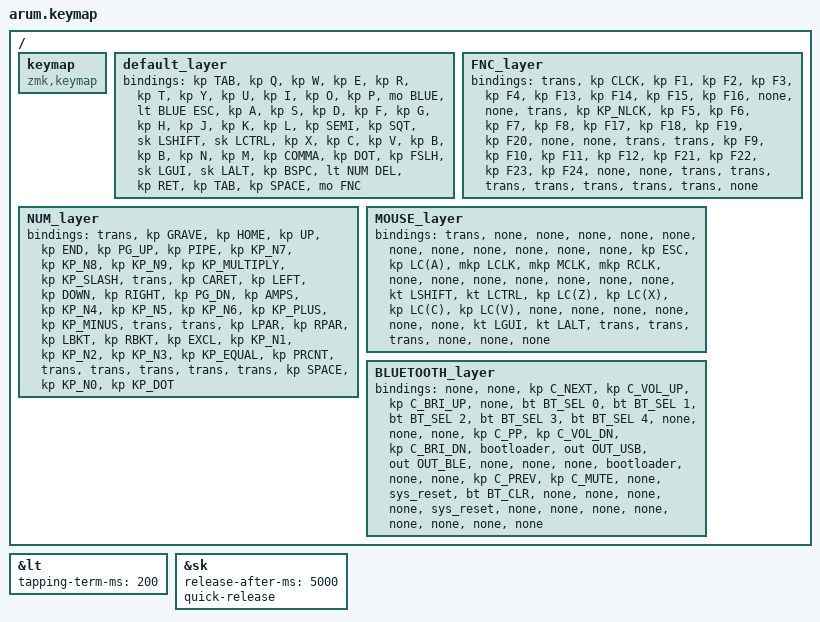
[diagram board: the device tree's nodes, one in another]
#include <behaviors.dtsi>
#include <dt-bindings/zmk/keys.h>
#include <dt-bindings/zmk/mouse.h>
#include <dt-bindings/zmk/outputs.h>
#include <dt-bindings/zmk/bt.h>

#define DEFAULT 0
#define NUM     1
#define FNC     2
#define MOUSE   3
#define BLUE    4

&lt {
    tapping-term-ms = <200>;
};

&sk {
    release-after-ms = <5000>;
    quick-release;
    /delete-property/ ignore-modifiers;
};

/ {
    keymap {
        compatible = "zmk,keymap";
    };

    default_layer {
// --------------------------------------------------------------------------------------------------------------------------------------------------------------------
// |   TAB   |    Q    |    W    |    E    |    R    |    T     |                              |    Y    |    U    |    I    |    O    |    P    |   BLUE  |
// |   ESC   |    A    |    S    |    D    |    F    |    G     |                              |    H    |    J    |    K    |    L    |    ;    |    '    |
// |  SHIFT  |   CTRL  |    Z    |    X    |    C    |    V     |                              |    B    |    N    |    M    |    ,    |    .    |    /    |  
//                     |   GUI   |   ALT   |   BSPC  |   DEL    | RETURN  |            |  TAB  |  SPACE  |                   |  R ALT  |
            bindings = <
    &kp TAB      &kp Q     &kp W    &kp E     &kp R     &kp T                                      &kp Y     &kp U     &kp I     &kp O     &kp P     &mo BLUE
    &lt BLUE ESC &kp A     &kp S    &kp D     &kp F     &kp G                                      &kp H     &kp J     &kp K     &kp L     &kp SEMI  &kp SQT
    &sk LSHIFT   &sk LCTRL &kp X    &kp C     &kp V     &kp B                                      &kp B     &kp N     &kp M     &kp COMMA &kp DOT   &kp FSLH
                           &sk LGUI &sk LALT  &kp BSPC  &lt NUM DEL &kp RET               &kp TAB  &kp SPACE                     &mo FNC
            >;
        };

        FNC_layer {
// --------------------------------------------------------------------------------------------------------------------------------------------------------------------
// |   TAB   |   CAPS  |   F1    |   F2    |   F3    |   F4    |                              |   F13   |   F14   |   F15   |   F16   |         |         |
// |   ESC   |   NUM   |   F5    |   F6    |   F7    |   F8    |                              |   F17   |   F18   |   F19   |   F20   |         |         |
// |  SHIFT  |   CTRL  |   F9    |   F10   |   F11   |   F12   |                              |   F21   |   F22   |   F23   |   F24   |         |         |  
//                     |   GUI   |   ALT   |   BSPC  |   DEL   | RETURN  |            |   TAB |  SPACE  |                   |         |
            bindings = <
    &trans     &kp CLCK    &kp F1   &kp F2    &kp F3    &kp F4                                  &kp F13   &kp F14   &kp F15   &kp F16   &none     &none
    &trans     &kp KP_NLCK &kp F5   &kp F6    &kp F7    &kp F8                                  &kp F17   &kp F18   &kp F19   &kp F20   &none     &none
    &trans     &trans      &kp F9   &kp F10   &kp F11   &kp F12                                 &kp F21   &kp F22   &kp F23   &kp F24   &none     &none
                           &trans   &trans    &trans    &trans    &trans               &trans   &trans                        &none
            >;

        };

        NUM_layer {
// --------------------------------------------------------------------------------------------------------------------------------------------------------------------
// |   TAB   |    `    |   HOME  |    UP   |   END   |   PGUP  |                              |    |    |    7    |    8    |    9    |    *    |    /    |
// |   ESC   |    ^    |   LEFT  |   DOWN  |  RIGHT  |   PGDN  |                              |    &    |    4    |    5    |    6    |    +    |    -    |
// |  SHIFT  |   CTRL  |   (     |     )   |    [    |     ]   |                              |    !    |    1    |    2    |    3    |    =    |    %    |  
//                     |   GUI   |   ALT   |   BSPC  |   DEL   | RETURN  |            | SPACE |    0    |                   |    .    |
            bindings = <
    &trans    &kp GRAVE  &kp HOME  &kp UP    &kp END   &kp PG_UP                               &kp PIPE  &kp KP_N7 &kp KP_N8 &kp KP_N9  &kp KP_MULTIPLY &kp KP_SLASH
    &trans    &kp CARET  &kp LEFT  &kp DOWN  &kp RIGHT &kp PG_DN                               &kp AMPS  &kp KP_N4 &kp KP_N5 &kp KP_N6  &kp KP_PLUS     &kp KP_MINUS
    &trans    &trans     &kp LPAR  &kp RPAR  &kp LBKT  &kp RBKT                                &kp EXCL  &kp KP_N1 &kp KP_N2 &kp KP_N3  &kp KP_EQUAL    &kp PRCNT
                         &trans    &trans    &trans    &trans     &trans             &kp SPACE &kp KP_N0                     &kp KP_DOT 
            >;

        };
        
        MOUSE_layer {
// --------------------------------------------------------------------------------------------------------------------------------------------------------------------
// |   TAB   |         |         |         |         |         |                              |         |         |         |         |         |         |
// |   ESC   |  SELALL |   LCLK  |   MCLK  |   RCLK  |         |                              |         |         |         |         |         |         |
// |  SHIFT  |   CTRL  |   UNDO  |   CUT   |   COPY  |  PASTE  |                              |         |         |         |         |         |         |
//                     |   GUI   |   ALT   |   BSPC  |   DEL   | RETURN  |            |       |         |                   |         |
            bindings = <
    &trans     &none     &none     &none     &none     &none                                   &none     &none     &none     &none     &none     &none
    &kp ESC    &kp LC(A) &mkp LCLK &mkp MCLK &mkp RCLK &none                                   &none     &none     &none     &none     &none     &none
    &kt LSHIFT &kt LCTRL &kp LC(Z) &kp LC(X) &kp LC(C) &kp LC(V)                               &none     &none     &none     &none     &none     &none
                         &kt LGUI  &kt LALT  &trans    &trans    &trans               &none    &none                         &none 
            >;
        };
        
        BLUETOOTH_layer {
// --------------------------------------------------------------------------------------------------------------------------------------------------------------------
// |         |         |  NEXT   |  VOLDN  |  BRIUP  |         |                              |   BT1   |   BT2   |   BT3   |   BT4   |   BT5   |         |
// |         |         |  PLAY   |  VOLUP  |  BRIDN  |  BOOT   |                              |         |         |         |         |         |  BOOT   |
// |         |         |  PREV   |  MUTE   |         |  RST    |                              |         |         |         |         |         |  RST    |
//                     |         |         |         |         |        |             |       |         |                   |         |
            bindings = <
    &none      &none     &kp C_NEXT &kp C_VOL_UP &kp C_BRI_UP &none                                    &bt BT_SEL 0 &bt BT_SEL 1 &bt BT_SEL 2 &bt BT_SEL 3 &bt BT_SEL 4  &none
    &none     &none     &kp C_PP   &kp C_VOL_DN &kp C_BRI_DN &bootloader                              &out OUT_USB &out OUT_BLE &none        &none        &none         &bootloader
    &none     &none     &kp C_PREV &kp C_MUTE   &none        &sys_reset                               &bt BT_CLR   &none        &none        &none        &none         &sys_reset
                        &none      &none        &none        &none     &none                  &none   &none                                  &none 
            >;
        };
};
